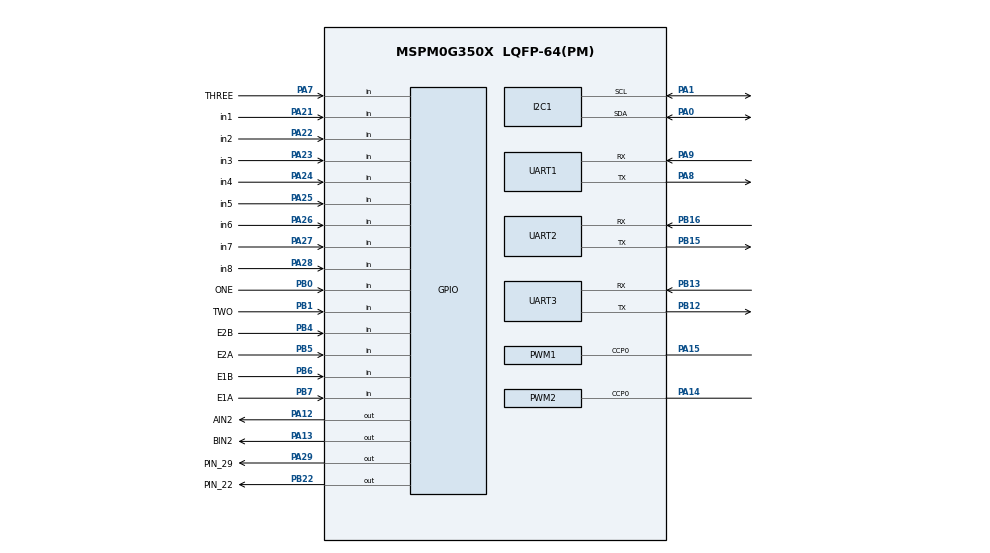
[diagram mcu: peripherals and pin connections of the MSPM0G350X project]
/**
 *
 * @cliArgs --device "MSPM0G350X" --part "Default" --package "LQFP-64(PM)" --product "mspm0_sdk@2.10.00.04"
 * @versions {"tool":"1.28.0+4712"}
 */

/**
 * Import the modules used in this configuration.
 */
const Board         = scripting.addModule("/ti/driverlib/Board");
const GPIO          = scripting.addModule("/ti/driverlib/GPIO", {}, false);
const GPIO1         = GPIO.addInstance();
const GPIO2         = GPIO.addInstance();
const GPIO3         = GPIO.addInstance();
const GPIO4         = GPIO.addInstance();
const GPIO5         = GPIO.addInstance();
const GPIO6         = GPIO.addInstance();
const GPIO7         = GPIO.addInstance();
const I2C           = scripting.addModule("/ti/driverlib/I2C", {}, false);
const I2C1          = I2C.addInstance();
const PWM           = scripting.addModule("/ti/driverlib/PWM", {}, false);
const PWM1          = PWM.addInstance();
const PWM2          = PWM.addInstance();
const SYSCTL        = scripting.addModule("/ti/driverlib/SYSCTL");
const TIMER         = scripting.addModule("/ti/driverlib/TIMER", {}, false);
const TIMER1        = TIMER.addInstance();
const UART          = scripting.addModule("/ti/driverlib/UART", {}, false);
const UART1         = UART.addInstance();
const UART2         = UART.addInstance();
const UART3         = UART.addInstance();
const ProjectConfig = scripting.addModule("/ti/project_config/ProjectConfig");

/**
 * Write custom configuration values to the imported modules.
 */
const divider6       = system.clockTree["PLL_CLK2X_DIV"];
divider6.divideValue = 4;

const divider7       = system.clockTree["PLL_PDIV"];
divider7.divideValue = 2;

const divider9       = system.clockTree["UDIV"];
divider9.divideValue = 2;

const multiplier2         = system.clockTree["PLL_QDIV"];
multiplier2.multiplyValue = 10;

const mux8       = system.clockTree["HSCLKMUX"];
mux8.inputSelect = "HSCLKMUX_SYSPLL2X";


GPIO1.port                                = "PORTB";
GPIO1.$name                               = "ENCODER_LEFT";
GPIO1.associatedPins.create(2);
GPIO1.associatedPins[0].direction         = "INPUT";
GPIO1.associatedPins[0].$name             = "E1A";
GPIO1.associatedPins[0].assignedPin       = "7";
GPIO1.associatedPins[0].interruptEn       = true;
GPIO1.associatedPins[0].interruptPriority = "2";
GPIO1.associatedPins[0].polarity          = "RISE";
GPIO1.associatedPins[0].pin.$assign       = "PB7";
GPIO1.associatedPins[1].direction         = "INPUT";
GPIO1.associatedPins[1].$name             = "E1B";
GPIO1.associatedPins[1].assignedPin       = "6";
GPIO1.associatedPins[1].pin.$assign       = "PB6";

GPIO2.port                                = "PORTB";
GPIO2.$name                               = "ENCODER_RIGHT";
GPIO2.associatedPins.create(2);
GPIO2.associatedPins[0].direction         = "INPUT";
GPIO2.associatedPins[0].$name             = "E2A";
GPIO2.associatedPins[0].assignedPin       = "5";
GPIO2.associatedPins[0].interruptEn       = true;
GPIO2.associatedPins[0].interruptPriority = "2";
GPIO2.associatedPins[0].polarity          = "RISE";
GPIO2.associatedPins[0].pin.$assign       = "PB5";
GPIO2.associatedPins[1].direction         = "INPUT";
GPIO2.associatedPins[1].$name             = "E2B";
GPIO2.associatedPins[1].assignedPin       = "4";
GPIO2.associatedPins[1].pin.$assign       = "PB4";

GPIO3.$name                              = "Track";
GPIO3.port                               = "PORTA";
GPIO3.portSegment                        = "Upper";
GPIO3.associatedPins.create(8);
GPIO3.associatedPins[0].direction        = "INPUT";
GPIO3.associatedPins[0].$name            = "in1";
GPIO3.associatedPins[0].internalResistor = "PULL_UP";
GPIO3.associatedPins[0].assignedPin      = "21";
GPIO3.associatedPins[0].pin.$assign      = "PA21";
GPIO3.associatedPins[1].$name            = "in2";
GPIO3.associatedPins[1].direction        = "INPUT";
GPIO3.associatedPins[1].internalResistor = "PULL_UP";
GPIO3.associatedPins[1].assignedPin      = "22";
GPIO3.associatedPins[1].pin.$assign      = "PA22";
GPIO3.associatedPins[2].$name            = "in3";
GPIO3.associatedPins[2].direction        = "INPUT";
GPIO3.associatedPins[2].assignedPin      = "23";
GPIO3.associatedPins[2].internalResistor = "PULL_UP";
GPIO3.associatedPins[2].pin.$assign      = "PA23";
GPIO3.associatedPins[3].$name            = "in4";
GPIO3.associatedPins[3].direction        = "INPUT";
GPIO3.associatedPins[3].assignedPin      = "24";
GPIO3.associatedPins[3].internalResistor = "PULL_UP";
GPIO3.associatedPins[3].pin.$assign      = "PA24";
GPIO3.associatedPins[4].$name            = "in5";
GPIO3.associatedPins[4].direction        = "INPUT";
GPIO3.associatedPins[4].assignedPin      = "25";
GPIO3.associatedPins[4].internalResistor = "PULL_UP";
GPIO3.associatedPins[4].pin.$assign      = "PA25";
GPIO3.associatedPins[5].$name            = "in6";
GPIO3.associatedPins[5].direction        = "INPUT";
GPIO3.associatedPins[5].assignedPin      = "26";
GPIO3.associatedPins[5].internalResistor = "PULL_UP";
GPIO3.associatedPins[5].pin.$assign      = "PA26";
GPIO3.associatedPins[6].$name            = "in7";
GPIO3.associatedPins[6].direction        = "INPUT";
GPIO3.associatedPins[6].assignedPin      = "27";
GPIO3.associatedPins[6].internalResistor = "PULL_UP";
GPIO3.associatedPins[6].pin.$assign      = "PA27";
GPIO3.associatedPins[7].$name            = "in8";
GPIO3.associatedPins[7].direction        = "INPUT";
GPIO3.associatedPins[7].assignedPin      = "28";
GPIO3.associatedPins[7].internalResistor = "PULL_UP";
GPIO3.associatedPins[7].pin.$assign      = "PA28";

GPIO4.$name                          = "Key";
GPIO4.associatedPins.create(3);
GPIO4.associatedPins[0].direction    = "INPUT";
GPIO4.associatedPins[0].assignedPort = "PORTB";
GPIO4.associatedPins[0].assignedPin  = "0";
GPIO4.associatedPins[0].$name        = "ONE";
GPIO4.associatedPins[0].pin.$assign  = "PB0";
GPIO4.associatedPins[1].direction    = "INPUT";
GPIO4.associatedPins[1].assignedPort = "PORTB";
GPIO4.associatedPins[1].assignedPin  = "1";
GPIO4.associatedPins[1].$name        = "TWO";
GPIO4.associatedPins[1].pin.$assign  = "PB1";
GPIO4.associatedPins[2].direction    = "INPUT";
GPIO4.associatedPins[2].$name        = "THREE";
GPIO4.associatedPins[2].assignedPort = "PORTA";
GPIO4.associatedPins[2].assignedPin  = "7";
GPIO4.associatedPins[2].pin.$assign  = "PA7";

GPIO5.$name                         = "LED";
GPIO5.port                          = "PORTB";
GPIO5.associatedPins[0].$name       = "PIN_22";
GPIO5.associatedPins[0].assignedPin = "22";
GPIO5.associatedPins[0].pin.$assign = "PB22";

GPIO6.$name                          = "CAR";
GPIO6.associatedPins.create(2);
GPIO6.associatedPins[0].$name        = "AIN2";
GPIO6.associatedPins[0].assignedPort = "PORTA";
GPIO6.associatedPins[0].initialValue = "SET";
GPIO6.associatedPins[0].assignedPin  = "12";
GPIO6.associatedPins[0].pin.$assign  = "PA12";
GPIO6.associatedPins[1].$name        = "BIN2";
GPIO6.associatedPins[1].assignedPort = "PORTA";
GPIO6.associatedPins[1].initialValue = "SET";
GPIO6.associatedPins[1].assignedPin  = "13";
GPIO6.associatedPins[1].pin.$assign  = "PA13";

GPIO7.$name                          = "BEEP";
GPIO7.associatedPins[0].$name        = "PIN_29";
GPIO7.associatedPins[0].assignedPort = "PORTA";
GPIO7.associatedPins[0].assignedPin  = "29";
GPIO7.associatedPins[0].pin.$assign  = "PA29";

I2C1.basicEnableController             = true;
I2C1.basicClockSourceDivider           = 4;
I2C1.$name                             = "I2C_OLED";
I2C1.peripheral.$assign                = "I2C0";
I2C1.peripheral.sdaPin.$assign         = "PA0";
I2C1.peripheral.sclPin.$assign         = "PA1";
I2C1.sdaPinConfig.$name                = "ti_driverlib_gpio_GPIOPinGeneric0";
I2C1.sdaPinConfig.hideOutputInversion  = scripting.forceWrite(false);
I2C1.sdaPinConfig.onlyInternalResistor = scripting.forceWrite(false);
I2C1.sdaPinConfig.passedPeripheralType = scripting.forceWrite("Digital");
I2C1.sclPinConfig.$name                = "ti_driverlib_gpio_GPIOPinGeneric1";
I2C1.sclPinConfig.hideOutputInversion  = scripting.forceWrite(false);
I2C1.sclPinConfig.onlyInternalResistor = scripting.forceWrite(false);
I2C1.sclPinConfig.passedPeripheralType = scripting.forceWrite("Digital");

PWM1.$name                              = "PWM_Left";
PWM1.timerStartTimer                    = true;
PWM1.timerCount                         = 32000;
PWM1.ccIndex                            = [0];
PWM1.PWM_CHANNEL_0.$name                = "ti_driverlib_pwm_PWMTimerCC1";
PWM1.ccp0PinConfig.direction            = scripting.forceWrite("OUTPUT");
PWM1.ccp0PinConfig.hideOutputInversion  = scripting.forceWrite(false);
PWM1.ccp0PinConfig.onlyInternalResistor = scripting.forceWrite(false);
PWM1.ccp0PinConfig.passedPeripheralType = scripting.forceWrite("Digital");
PWM1.ccp0PinConfig.$name                = "ti_driverlib_gpio_GPIOPinGeneric6";
PWM1.peripheral.$assign                 = "TIMA1";
PWM1.peripheral.ccp0Pin.$assign         = "PA15";

PWM2.$name                              = "PWM_Right";
PWM2.timerStartTimer                    = true;
PWM2.timerCount                         = 32000;
PWM2.ccIndex                            = [0];
PWM2.PWM_CHANNEL_0.$name                = "ti_driverlib_pwm_PWMTimerCC0";
PWM2.ccp0PinConfig.direction            = scripting.forceWrite("OUTPUT");
PWM2.ccp0PinConfig.hideOutputInversion  = scripting.forceWrite(false);
PWM2.ccp0PinConfig.onlyInternalResistor = scripting.forceWrite(false);
PWM2.ccp0PinConfig.passedPeripheralType = scripting.forceWrite("Digital");
PWM2.ccp0PinConfig.$name                = "ti_driverlib_gpio_GPIOPinGeneric7";
PWM2.peripheral.$assign                 = "TIMG12";
PWM2.peripheral.ccp0Pin.$assign         = "PA14";

SYSCTL.clockTreeEn = true;

TIMER1.$name              = "TIMER_0";
TIMER1.timerClkPrescale   = 256;
TIMER1.timerMode          = "PERIODIC";
TIMER1.timerPeriod        = "1ms";
TIMER1.interrupts         = ["ZERO"];
TIMER1.timerStartTimer    = true;
TIMER1.peripheral.$assign = "TIMA0";

UART1.interruptPriority                = "2";
UART1.$name                            = "UART_WIT";
UART1.targetBaudRate                   = 115200;
UART1.enableFIFO                       = true;
UART1.rxTimeoutValue                   = 1;
UART1.enabledInterrupts                = ["RX_TIMEOUT_ERROR"];
UART1.enabledDMARXTriggers             = "DL_UART_DMA_INTERRUPT_RX";
UART1.peripheral.$assign               = "UART1";
UART1.peripheral.rxPin.$assign         = "PA9";
UART1.peripheral.txPin.$assign         = "PA8";
UART1.txPinConfig.direction            = scripting.forceWrite("OUTPUT");
UART1.txPinConfig.hideOutputInversion  = scripting.forceWrite(false);
UART1.txPinConfig.onlyInternalResistor = scripting.forceWrite(false);
UART1.txPinConfig.passedPeripheralType = scripting.forceWrite("Digital");
UART1.txPinConfig.$name                = "ti_driverlib_gpio_GPIOPinGeneric2";
UART1.rxPinConfig.hideOutputInversion  = scripting.forceWrite(false);
UART1.rxPinConfig.onlyInternalResistor = scripting.forceWrite(false);
UART1.rxPinConfig.passedPeripheralType = scripting.forceWrite("Digital");
UART1.rxPinConfig.$name                = "ti_driverlib_gpio_GPIOPinGeneric3";
UART1.DMA_CHANNEL_RX.$name             = "DMA_WIT";
UART1.DMA_CHANNEL_RX.addressMode       = "f2b";
UART1.DMA_CHANNEL_RX.srcLength         = "BYTE";
UART1.DMA_CHANNEL_RX.dstLength         = "BYTE";

UART2.$name                            = "UART_2";
UART2.interruptPriority                = "2";
UART2.targetBaudRate                   = 115200;
UART2.peripheral.$assign               = "UART2";
UART2.peripheral.rxPin.$assign         = "PB16";
UART2.peripheral.txPin.$assign         = "PB15";
UART2.txPinConfig.direction            = scripting.forceWrite("OUTPUT");
UART2.txPinConfig.hideOutputInversion  = scripting.forceWrite(false);
UART2.txPinConfig.onlyInternalResistor = scripting.forceWrite(false);
UART2.txPinConfig.passedPeripheralType = scripting.forceWrite("Digital");
UART2.txPinConfig.$name                = "ti_driverlib_gpio_GPIOPinGeneric4";
UART2.rxPinConfig.hideOutputInversion  = scripting.forceWrite(false);
UART2.rxPinConfig.onlyInternalResistor = scripting.forceWrite(false);
UART2.rxPinConfig.passedPeripheralType = scripting.forceWrite("Digital");
UART2.rxPinConfig.$name                = "ti_driverlib_gpio_GPIOPinGeneric5";

UART3.$name                            = "UART_3";
UART3.peripheral.$assign               = "UART3";
UART3.peripheral.rxPin.$assign         = "PB13";
UART3.peripheral.txPin.$assign         = "PB12";
UART3.txPinConfig.direction            = scripting.forceWrite("OUTPUT");
UART3.txPinConfig.hideOutputInversion  = scripting.forceWrite(false);
UART3.txPinConfig.onlyInternalResistor = scripting.forceWrite(false);
UART3.txPinConfig.passedPeripheralType = scripting.forceWrite("Digital");
UART3.txPinConfig.$name                = "ti_driverlib_gpio_GPIOPinGeneric8";
UART3.rxPinConfig.hideOutputInversion  = scripting.forceWrite(false);
UART3.rxPinConfig.onlyInternalResistor = scripting.forceWrite(false);
UART3.rxPinConfig.passedPeripheralType = scripting.forceWrite("Digital");
UART3.rxPinConfig.$name                = "ti_driverlib_gpio_GPIOPinGeneric9";

ProjectConfig.deviceSpin = "MSPM0G3507";

/**
 * Pinmux solution for unlocked pins/peripherals. This ensures that minor changes to the automatic solver in a future
 * version of the tool will not impact the pinmux you originally saw.  These lines can be completely deleted in order to
 * re-solve from scratch.
 */
Board.peripheral.$suggestSolution                = "DEBUGSS";
Board.peripheral.swclkPin.$suggestSolution       = "PA20";
Board.peripheral.swdioPin.$suggestSolution       = "PA19";
UART1.DMA_CHANNEL_RX.peripheral.$suggestSolution = "DMA_CH0";
